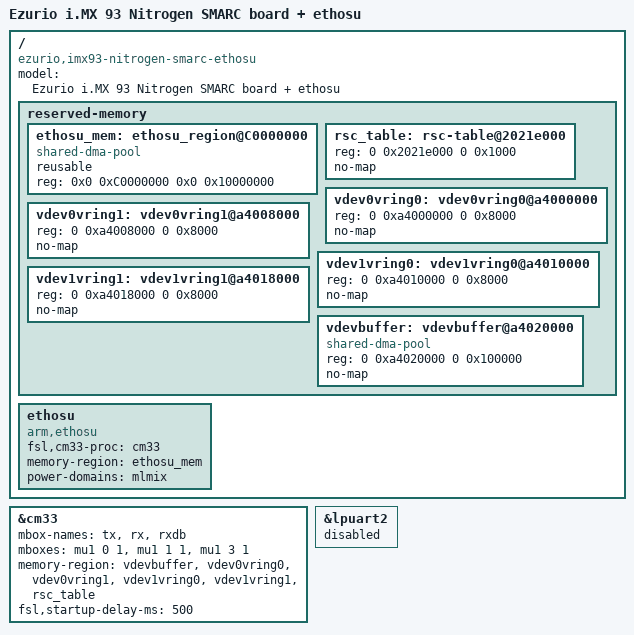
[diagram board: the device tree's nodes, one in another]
// SPDX-License-Identifier: (GPL-2.0+ OR MIT)
/*
 * Copyright 2025 Ezurio LLC
 */

#include "imx93-nitrogen-smarc.dts"

/ {
	model = "Ezurio i.MX 93 Nitrogen SMARC board + ethosu";
	compatible = "ezurio,imx93-nitrogen-smarc-ethosu", "fsl,imx93";

	reserved-memory {
		ethosu_mem: ethosu_region@C0000000 {
			compatible = "shared-dma-pool";
			reusable;
			reg = <0x0 0xC0000000 0x0 0x10000000>;
		};

		rsc_table: rsc-table@2021e000 {
			reg = <0 0x2021e000 0 0x1000>;
			no-map;
		};

		vdev0vring0: vdev0vring0@a4000000 {
			reg = <0 0xa4000000 0 0x8000>;
			no-map;
		};

		vdev0vring1: vdev0vring1@a4008000 {
			reg = <0 0xa4008000 0 0x8000>;
			no-map;
		};

		vdev1vring0: vdev1vring0@a4010000 {
			reg = <0 0xa4010000 0 0x8000>;
			no-map;
		};

		vdev1vring1: vdev1vring1@a4018000 {
			reg = <0 0xa4018000 0 0x8000>;
			no-map;
		};

		vdevbuffer: vdevbuffer@a4020000 {
			compatible = "shared-dma-pool";
			reg = <0 0xa4020000 0 0x100000>;
			no-map;
		};
	};

	ethosu {
		compatible = "arm,ethosu";
		fsl,cm33-proc = <&cm33>;
		memory-region = <&ethosu_mem>;
		power-domains = <&mlmix>;
	};
};

&cm33 {
	mbox-names = "tx", "rx", "rxdb";
	mboxes = <&mu1 0 1
		  &mu1 1 1
		  &mu1 3 1>;
	memory-region = <&vdevbuffer>, <&vdev0vring0>, <&vdev0vring1>,
			<&vdev1vring0>, <&vdev1vring1>, <&rsc_table>;
	fsl,startup-delay-ms = <500>;
	status = "okay";
};

&lpuart2 {
	status = "disabled";
};
